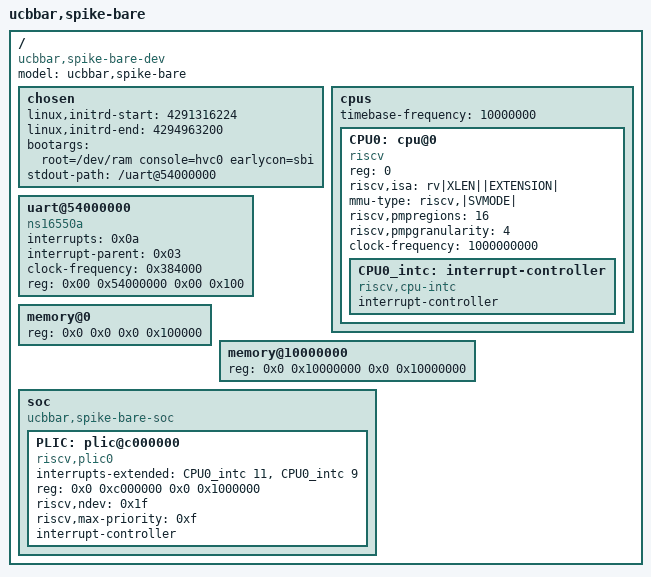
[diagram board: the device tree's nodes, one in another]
/dts-v1/;

/ {
  #address-cells = <2>;
  #size-cells = <2>;
  compatible = "ucbbar,spike-bare-dev";
  model = "ucbbar,spike-bare";
  chosen {
    linux,initrd-start = <4291316224>;
    linux,initrd-end = <4294963200>;
    bootargs = "root=/dev/ram console=hvc0 earlycon=sbi";
    /* bootargs = [00]; */
    stdout-path = "/uart@54000000";
  };
  cpus {
    #address-cells = <1>;
    #size-cells = <0>;
    timebase-frequency = <10000000>;
    CPU0: cpu@0 {
      device_type = "cpu";
      reg = <0>;
      status = "okay";
      compatible = "riscv";
      riscv,isa = "rv|XLEN||EXTENSION|";
      mmu-type = "riscv,|SVMODE|";
      riscv,pmpregions = <16>;
      riscv,pmpgranularity = <4>;
      clock-frequency = <1000000000>;
      CPU0_intc: interrupt-controller {
        #interrupt-cells = <1>;
        interrupt-controller;
        compatible = "riscv,cpu-intc";
      };
    };
  };

  uart@54000000 {
    interrupts = <0x0a>;
    interrupt-parent = <0x03>;
    clock-frequency = <0x384000>;
    reg = <0x00 0x54000000 0x00 0x100>;
    compatible = "ns16550a";
  };

  memory@0 {
    device_type = "memory";
    reg = <0x0 0x0 0x0 0x100000>;
  };
  memory@10000000 {
    device_type = "memory";
    reg = <0x0 0x10000000 0x0 0x10000000>;
  };
  soc {
    #address-cells = <2>;
    #size-cells = <2>;
    compatible = "ucbbar,spike-bare-soc", "simple-bus";
    ranges;
    /*
    clint@2000000 {
      compatible = "riscv,clint0";
      interrupts-extended = <&CPU0_intc 3 &CPU0_intc 7 >;
      reg = <0x0 0x2000000 0x0 0xc0000>;
    };
    */
    PLIC: plic@c000000 {
      compatible = "riscv,plic0";
      #address-cells = <2>;
      interrupts-extended = <&CPU0_intc 11 &CPU0_intc 9 >;
      reg = <0x0 0xc000000 0x0 0x1000000>;
      riscv,ndev = <0x1f>;
      riscv,max-priority = <0xf>;
      #interrupt-cells = <1>;
      interrupt-controller;
    };
  };
};
